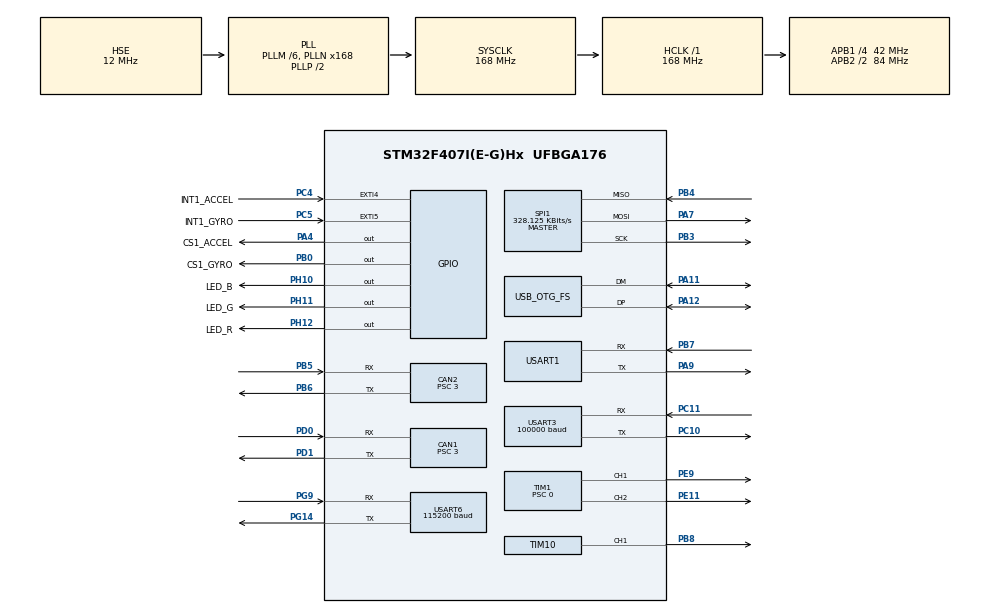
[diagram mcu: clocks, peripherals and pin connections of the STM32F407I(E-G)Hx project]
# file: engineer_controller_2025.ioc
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CAN1.ABOM=ENABLE
CAN1.AWUM=ENABLE
CAN1.BS1=CAN_BS1_7TQ
CAN1.BS2=CAN_BS2_6TQ
CAN1.CalculateBaudRate=1000000
CAN1.CalculateTimeBit=1000
CAN1.CalculateTimeQuantum=71.42857142857143
CAN1.Mode=CAN_MODE_NORMAL
CAN1.NART=ENABLE
CAN1.Prescaler=3
CAN1.TXFP=ENABLE
CAN2.ABOM=ENABLE
CAN2.AWUM=ENABLE
CAN2.BS1=CAN_BS1_7TQ
CAN2.BS2=CAN_BS2_6TQ
CAN2.CalculateBaudRate=1000000
CAN2.CalculateTimeBit=1000
CAN2.CalculateTimeQuantum=71.42857142857143
CAN2.NART=ENABLE
CAN2.Prescaler=3
CAN2.RFLM=DISABLE
CAN2.TTCM=DISABLE
CAN2.TXFP=ENABLE
Dma.Request0=USART3_RX
Dma.Request1=SPI1_RX
Dma.Request2=SPI1_TX
Dma.Request3=TIM1_CH1
Dma.Request4=TIM1_CH2
Dma.Request5=USART1_RX
Dma.Request6=USART1_TX
Dma.SPI1_RX.1.Direction=DMA_PERIPH_TO_MEMORY
Dma.SPI1_RX.1.FIFOMode=DMA_FIFOMODE_DISABLE
Dma.SPI1_RX.1.Instance=DMA2_Stream0
Dma.SPI1_RX.1.MemDataAlignment=DMA_MDATAALIGN_BYTE
Dma.SPI1_RX.1.MemInc=DMA_MINC_ENABLE
Dma.SPI1_RX.1.Mode=DMA_NORMAL
Dma.SPI1_RX.1.PeriphDataAlignment=DMA_PDATAALIGN_BYTE
Dma.SPI1_RX.1.PeriphInc=DMA_PINC_DISABLE
Dma.SPI1_RX.1.Priority=DMA_PRIORITY_VERY_HIGH
Dma.SPI1_TX.2.Direction=DMA_MEMORY_TO_PERIPH
Dma.SPI1_TX.2.FIFOMode=DMA_FIFOMODE_DISABLE
Dma.SPI1_TX.2.Instance=DMA2_Stream3
Dma.SPI1_TX.2.MemDataAlignment=DMA_MDATAALIGN_BYTE
Dma.SPI1_TX.2.MemInc=DMA_MINC_ENABLE
Dma.SPI1_TX.2.Mode=DMA_NORMAL
Dma.SPI1_TX.2.PeriphDataAlignment=DMA_PDATAALIGN_BYTE
Dma.SPI1_TX.2.PeriphInc=DMA_PINC_DISABLE
Dma.SPI1_TX.2.Priority=DMA_PRIORITY_VERY_HIGH
Dma.TIM1_CH1.3.Direction=DMA_MEMORY_TO_PERIPH
Dma.TIM1_CH1.3.FIFOMode=DMA_FIFOMODE_DISABLE
Dma.TIM1_CH1.3.Instance=DMA2_Stream1
Dma.TIM1_CH1.3.MemDataAlignment=DMA_MDATAALIGN_HALFWORD
Dma.TIM1_CH1.3.MemInc=DMA_MINC_ENABLE
Dma.TIM1_CH1.3.Mode=DMA_CIRCULAR
Dma.TIM1_CH1.3.PeriphDataAlignment=DMA_PDATAALIGN_HALFWORD
Dma.TIM1_CH1.3.PeriphInc=DMA_PINC_DISABLE
Dma.TIM1_CH1.3.Priority=DMA_PRIORITY_HIGH
Dma.TIM1_CH2.4.Direction=DMA_MEMORY_TO_PERIPH
Dma.TIM1_CH2.4.FIFOMode=DMA_FIFOMODE_DISABLE
Dma.TIM1_CH2.4.Instance=DMA2_Stream2
Dma.TIM1_CH2.4.MemDataAlignment=DMA_MDATAALIGN_HALFWORD
Dma.TIM1_CH2.4.MemInc=DMA_MINC_ENABLE
Dma.TIM1_CH2.4.Mode=DMA_NORMAL
Dma.TIM1_CH2.4.PeriphDataAlignment=DMA_PDATAALIGN_HALFWORD
Dma.TIM1_CH2.4.PeriphInc=DMA_PINC_DISABLE
Dma.TIM1_CH2.4.Priority=DMA_PRIORITY_HIGH
Dma.USART1_RX.5.Direction=DMA_PERIPH_TO_MEMORY
Dma.USART1_RX.5.FIFOMode=DMA_FIFOMODE_DISABLE
Dma.USART1_RX.5.Instance=DMA2_Stream5
Dma.USART1_RX.5.MemDataAlignment=DMA_MDATAALIGN_BYTE
Dma.USART1_RX.5.MemInc=DMA_MINC_ENABLE
Dma.USART1_RX.5.Mode=DMA_NORMAL
Dma.USART1_RX.5.PeriphDataAlignment=DMA_PDATAALIGN_BYTE
Dma.USART1_RX.5.PeriphInc=DMA_PINC_DISABLE
Dma.USART1_RX.5.Priority=DMA_PRIORITY_LOW
Dma.USART1_TX.6.Direction=DMA_MEMORY_TO_PERIPH
Dma.USART1_TX.6.FIFOMode=DMA_FIFOMODE_DISABLE
Dma.USART1_TX.6.Instance=DMA2_Stream7
Dma.USART1_TX.6.MemDataAlignment=DMA_MDATAALIGN_BYTE
Dma.USART1_TX.6.MemInc=DMA_MINC_ENABLE
Dma.USART1_TX.6.Mode=DMA_NORMAL
Dma.USART1_TX.6.PeriphDataAlignment=DMA_PDATAALIGN_BYTE
Dma.USART1_TX.6.PeriphInc=DMA_PINC_DISABLE
Dma.USART1_TX.6.Priority=DMA_PRIORITY_LOW
Dma.USART3_RX.0.Direction=DMA_PERIPH_TO_MEMORY
Dma.USART3_RX.0.FIFOMode=DMA_FIFOMODE_DISABLE
Dma.USART3_RX.0.Instance=DMA1_Stream1
Dma.USART3_RX.0.MemDataAlignment=DMA_MDATAALIGN_BYTE
Dma.USART3_RX.0.MemInc=DMA_MINC_ENABLE
Dma.USART3_RX.0.Mode=DMA_NORMAL
Dma.USART3_RX.0.PeriphDataAlignment=DMA_PDATAALIGN_BYTE
Dma.USART3_RX.0.PeriphInc=DMA_PINC_DISABLE
Dma.USART3_RX.0.Priority=DMA_PRIORITY_HIGH
FREERTOS.BinarySemaphores01=judgementInitBinarySem,Dynamic,NULL,Depleted;ArmMotor1UpdateBinarySem,Dynamic,NULL,Depleted;ArmMotor2UpdateBinarySem,Dynamic,NULL,Depleted;ArmMotor3UpdateBinarySem,Dynamic,NULL,Depleted;ArmMotor4UpdateBinarySem,Dynamic,NULL,Depleted;ArmMotor5UpdateBinarySem,Dynamic,NULL,Depleted;ArmMotor6UpdateBinarySem,Dynamic,NULL,Depleted
FREERTOS.CountingSemaphores01=CAN1CountingSem,3,Dynamic,NULL,3;CAN2CountingSem,3,Dynamic,NULL,3
FREERTOS.Events01=refereeEvent,Dynamic,NULL
FREERTOS.Queues01=CAN1SendQueue,16,can_device_transmit_member,0,Dynamic,NULL,NULL;CAN2SendQueue,16,can_device_transmit_member,0,Dynamic,NULL,NULL
FREERTOS.Tasks01=defaultTask,24,256,StartDefaultTask,Default,NULL,Dynamic,NULL,NULL;CAN1_Send_Task,40,256,CAN1Send_Task,As weak,NULL,Dynamic,NULL,NULL;CAN2_Send_Task,40,256,CAN2Send_Task,As weak,NULL,Dynamic,NULL,NULL;judgeCtrltask,24,256,judgeCtrl_task,As weak,NULL,Dynamic,NULL,NULL;armtask,24,256,arm_task,As weak,NULL,Dynamic,NULL,NULL;refereeupdatetask,24,256,refereeupdate_task,As weak,NULL,Dynamic,NULL,NULL;lostchecktask,24,512,lost_check_task,As weak,NULL,Dynamic,NULL,NULL
FREERTOS.configMAX_TASK_NAME_LEN=32
FREERTOS.configMINIMAL_STACK_SIZE=128
FREERTOS.configTOTAL_HEAP_SIZE=80000
FREERTOS.configUSE_NEWLIB_REENTRANT=1
IWDG.Prescaler=IWDG_PRESCALER_4
Mcu.Family=STM32F4
Mcu.Name=STM32F407I(E-G)Hx
Mcu.Package=UFBGA176
NVIC.CAN1_RX0_IRQn=true\:5\:0\:false\:false\:true\:true\:true\:true\:true
NVIC.CAN1_TX_IRQn=true\:5\:0\:false\:false\:true\:true\:true\:true\:true
NVIC.CAN2_RX1_IRQn=true\:5\:0\:false\:false\:true\:true\:true\:true\:true
NVIC.CAN2_TX_IRQn=true\:5\:0\:false\:false\:true\:true\:true\:true\:true
NVIC.DMA1_Stream1_IRQn=true\:5\:0\:false\:false\:true\:true\:false\:true\:true
NVIC.DMA2_Stream0_IRQn=true\:5\:0\:false\:false\:true\:false\:false\:true\:true
NVIC.DMA2_Stream1_IRQn=true\:5\:0\:false\:false\:true\:false\:false\:true\:true
NVIC.DMA2_Stream2_IRQn=true\:5\:0\:false\:false\:true\:true\:false\:true\:true
NVIC.DMA2_Stream3_IRQn=true\:5\:0\:false\:false\:true\:true\:false\:true\:true
NVIC.DMA2_Stream5_IRQn=true\:5\:0\:false\:false\:true\:true\:false\:true\:true
NVIC.DMA2_Stream7_IRQn=true\:5\:0\:false\:false\:true\:true\:false\:true\:true
NVIC.OTG_FS_IRQn=true\:5\:0\:false\:false\:true\:true\:false\:true\:true
NVIC.PriorityGroup=NVIC_PRIORITYGROUP_4
NVIC.TIM7_IRQn=true\:0\:0\:true\:false\:true\:false\:false\:true\:true
NVIC.TimeBase=TIM7_IRQn
NVIC.TimeBaseIP=TIM7
NVIC.USART1_IRQn=true\:5\:0\:false\:false\:true\:true\:true\:true\:true
NVIC.USART3_IRQn=true\:5\:0\:false\:false\:true\:true\:true\:true\:true
NVIC.USART6_IRQn=true\:5\:0\:false\:false\:true\:true\:true\:true\:true
PA11.Mode=Device_Only
PA11.Signal=USB_OTG_FS_DM
PA12.Mode=Device_Only
PA12.Signal=USB_OTG_FS_DP
PA13.Mode=Serial_Wire
PA13.Signal=SYS_JTMS-SWDIO
PA14.Mode=Serial_Wire
PA14.Signal=SYS_JTCK-SWCLK
PA4.GPIO_Label=CS1_ACCEL
PA4.GPIO_PuPd=GPIO_PULLUP
PA4.GPIO_Speed=GPIO_SPEED_FREQ_HIGH
PA4.PinState=GPIO_PIN_SET
PA4.Signal=GPIO_Output
PA7.Mode=Full_Duplex_Master
PA7.Signal=SPI1_MOSI
PA9.Mode=Asynchronous
PA9.Signal=USART1_TX
PB0.GPIO_Label=CS1_GYRO
PB0.GPIO_PuPd=GPIO_PULLUP
PB0.GPIO_Speed=GPIO_SPEED_FREQ_HIGH
PB0.PinState=GPIO_PIN_SET
PB0.Signal=GPIO_Output
PB3.Mode=Full_Duplex_Master
PB3.Signal=SPI1_SCK
PB4.Mode=Full_Duplex_Master
PB4.Signal=SPI1_MISO
PB5.Mode=CAN_Activate
PB5.Signal=CAN2_RX
PB6.Mode=CAN_Activate
PB6.Signal=CAN2_TX
PB7.Mode=Asynchronous
PB7.Signal=USART1_RX
PB8.Signal=S_TIM10_CH1
PC10.Mode=Asynchronous
PC10.Signal=USART3_TX
PC11.Mode=Asynchronous
PC11.Signal=USART3_RX
PC4.GPIO_Label=INT1_ACCEL
PC4.GPIO_PuPd=GPIO_PULLUP
PC4.Signal=GPXTI4
PC5.GPIO_Label=INT1_GYRO
PC5.GPIO_PuPd=GPIO_PULLUP
PC5.Signal=GPXTI5
PD0.Mode=CAN_Activate
PD0.Signal=CAN1_RX
PD1.Mode=CAN_Activate
PD1.Signal=CAN1_TX
PE11.Signal=S_TIM1_CH2
PE9.Signal=S_TIM1_CH1
PG14.Mode=Asynchronous
PG14.Signal=USART6_TX
PG9.Mode=Asynchronous
PG9.Signal=USART6_RX
PH0-OSC_IN.Mode=HSE-External-Oscillator
PH0-OSC_IN.Signal=RCC_OSC_IN
PH1-OSC_OUT.Mode=HSE-External-Oscillator
PH1-OSC_OUT.Signal=RCC_OSC_OUT
PH10.GPIO_Label=LED_B
PH10.GPIO_PuPd=GPIO_PULLDOWN
PH10.Signal=GPIO_Output
PH11.GPIO_Label=LED_G
PH11.GPIO_PuPd=GPIO_PULLDOWN
PH11.Signal=GPIO_Output
PH12.GPIO_Label=LED_R
PH12.GPIO_PuPd=GPIO_PULLDOWN
PH12.Signal=GPIO_Output
ProjectManager.HeapSize=0x200
ProjectManager.StackSize=0x400
ProjectManager.TargetToolchain=STM32CubeIDE
RCC.48MHZClocksFreq_Value=48000000
RCC.AHBFreq_Value=168000000
RCC.APB1CLKDivider=RCC_HCLK_DIV4
RCC.APB1Freq_Value=42000000
RCC.APB1TimFreq_Value=84000000
RCC.APB2CLKDivider=RCC_HCLK_DIV2
RCC.APB2Freq_Value=84000000
RCC.APB2TimFreq_Value=168000000
RCC.CortexFreq_Value=168000000
RCC.HCLKFreq_Value=168000000
RCC.HSE_VALUE=12000000
RCC.HSI_VALUE=16000000
RCC.LSE_VALUE=32768
RCC.PLLM=6
RCC.PLLN=168
RCC.PLLQ=7
RCC.SYSCLKFreq_VALUE=168000000
RCC.SYSCLKSource=RCC_SYSCLKSOURCE_PLLCLK
RCC.VCOOutputFreq_Value=336000000
SH.S_TIM10_CH1.0=TIM10_CH1,PWM Generation1 CH1
SH.S_TIM1_CH1.0=TIM1_CH1,PWM Generation1 CH1
SH.S_TIM1_CH2.0=TIM1_CH2,PWM Generation2 CH2
SPI1.BaudRatePrescaler=SPI_BAUDRATEPRESCALER_256
SPI1.CLKPhase=SPI_PHASE_2EDGE
SPI1.CLKPolarity=SPI_POLARITY_HIGH
SPI1.CalculateBaudRate=328.125 KBits/s
SPI1.Direction=SPI_DIRECTION_2LINES
SPI1.Mode=SPI_MODE_MASTER
SPI1.VirtualType=VM_MASTER
STMicroelectronics.X-CUBE-ALGOBUILD.1.3.0.LibraryCcDSPOoLibraryJjDSPOoLibrary=true
TIM1.AutoReloadPreload=TIM_AUTORELOAD_PRELOAD_DISABLE
TIM1.Channel-PWM\ Generation1\ CH1=TIM_CHANNEL_1
TIM1.Channel-PWM\ Generation2\ CH2=TIM_CHANNEL_2
TIM1.Period=210-1
TIM1.Prescaler=0
TIM10.Channel=TIM_CHANNEL_1
TIM10.Period=5000-1
USART1.VirtualMode=VM_ASYNC
USART3.BaudRate=100000
USART3.Parity=PARITY_EVEN
USART3.VirtualMode=VM_ASYNC
USART3.WordLength=WORDLENGTH_9B
USART6.BaudRate=115200
USART6.VirtualMode=VM_ASYNC
USB_DEVICE.CLASS_NAME_FS=CDC
USB_DEVICE.VirtualMode-CDC_FS=Cdc
USB_DEVICE.VirtualModeFS=Cdc_FS
USB_OTG_FS.VirtualMode=Device_Only
VP_FREERTOS_VS_CMSIS_V2.Mode=CMSIS_V2
VP_IWDG_VS_IWDG.Mode=IWDG_Activate
VP_STMicroelectronics.X-CUBE-ALGOBUILD_VS_DSPOoLibraryJjLibrary_1.3.0_1.3.0.Mode=DSPOoLibraryJjLibrary
VP_SYS_VS_tim7.Mode=TIM7
VP_TIM10_VS_ClockSourceINT.Mode=Enable_Timer
VP_TIM1_VS_ClockSourceINT.Mode=Internal
VP_USB_DEVICE_VS_USB_DEVICE_CDC_FS.Mode=CDC_FS
board=custom

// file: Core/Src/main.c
/* USER CODE BEGIN Header */
/**
  ******************************************************************************
  * @file           : main.c
  * @brief          : Main program body
  ******************************************************************************
  * @attention
  *
  * Copyright (c) 2025 STMicroelectronics.
  * All rights reserved.
  *
  * This software is licensed under terms that can be found in the LICENSE file
  * in the root directory of this software component.
  * If no LICENSE file comes with this software, it is provided AS-IS.
  *
  ******************************************************************************
  */
/* USER CODE END Header */
#include "main.h"
#include "cmsis_os.h"
#include "can.h"
#include "dma.h"
#include "iwdg.h"
#include "spi.h"
#include "tim.h"
#include "usart.h"
#include "usb_device.h"
#include "gpio.h"

/* USER CODE BEGIN Includes */
#include "compatible.h"
#include "bsp_dwt.h"
/* USER CODE END Includes */

void SystemClock_Config(void);
void MX_FREERTOS_Init(void);

int main(void)
{

  /* USER CODE BEGIN 1 */
    __HAL_RCC_SYSCLK_CONFIG(RCC_SYSCLKSOURCE_HSI);
  /* USER CODE END 1 */

  /* MCU Configuration--------------------------------------------------------*/

  /* Reset of all peripherals, Initializes the Flash interface and the Systick. */
  HAL_Init();

  /* Configure the system clock */
  SystemClock_Config();

  /* Initialize all configured peripherals */
  MX_GPIO_Init();
  MX_DMA_Init();
  MX_CAN1_Init();
  MX_CAN2_Init();
  MX_TIM1_Init();
  MX_USART3_UART_Init();
  MX_SPI1_Init();
  MX_TIM10_Init();
  MX_USART6_UART_Init();
  MX_IWDG_Init();
  MX_USART1_UART_Init();
  /* USER CODE BEGIN 2 */
    DWT_Init(168);
    bsp_can_init();
  /* USER CODE END 2 */

  /* Init scheduler */
  osKernelInitialize();  /* Call init function for freertos objects (in cmsis_os2.c) */
  MX_FREERTOS_Init();

  /* Start scheduler */
  osKernelStart();

  /* We should never get here as control is now taken by the scheduler */

  /* Infinite loop */
  while (1)
  {

  }
}

void SystemClock_Config(void)
{
  RCC_OscInitTypeDef RCC_OscInitStruct = {0};
  RCC_ClkInitTypeDef RCC_ClkInitStruct = {0};

  /** Configure the main internal regulator output voltage
  */
  __HAL_RCC_PWR_CLK_ENABLE();
  __HAL_PWR_VOLTAGESCALING_CONFIG(PWR_REGULATOR_VOLTAGE_SCALE1);

  /** Initializes the RCC Oscillators according to the specified parameters
  * in the RCC_OscInitTypeDef structure.
  */
  RCC_OscInitStruct.OscillatorType = RCC_OSCILLATORTYPE_LSI|RCC_OSCILLATORTYPE_HSE;
  RCC_OscInitStruct.HSEState = RCC_HSE_ON;
  RCC_OscInitStruct.LSIState = RCC_LSI_ON;
  RCC_OscInitStruct.PLL.PLLState = RCC_PLL_ON;
  RCC_OscInitStruct.PLL.PLLSource = RCC_PLLSOURCE_HSE;
  RCC_OscInitStruct.PLL.PLLM = 6;
  RCC_OscInitStruct.PLL.PLLN = 168;
  RCC_OscInitStruct.PLL.PLLP = RCC_PLLP_DIV2;
  RCC_OscInitStruct.PLL.PLLQ = 7;
  if (HAL_RCC_OscConfig(&RCC_OscInitStruct) != HAL_OK)
  {
    Error_Handler();
  }

  /** Initializes the CPU, AHB and APB buses clocks
  */
  RCC_ClkInitStruct.ClockType = RCC_CLOCKTYPE_HCLK|RCC_CLOCKTYPE_SYSCLK
                              |RCC_CLOCKTYPE_PCLK1|RCC_CLOCKTYPE_PCLK2;
  RCC_ClkInitStruct.SYSCLKSource = RCC_SYSCLKSOURCE_PLLCLK;
  RCC_ClkInitStruct.AHBCLKDivider = RCC_SYSCLK_DIV1;
  RCC_ClkInitStruct.APB1CLKDivider = RCC_HCLK_DIV4;
  RCC_ClkInitStruct.APB2CLKDivider = RCC_HCLK_DIV2;

  if (HAL_RCC_ClockConfig(&RCC_ClkInitStruct, FLASH_LATENCY_5) != HAL_OK)
  {
    Error_Handler();
  }
}

void HAL_TIM_PeriodElapsedCallback(TIM_HandleTypeDef *htim)
{
  if (htim->Instance == TIM7)
  {
    HAL_IncTick();
  }
}

void Error_Handler(void)
{
  __disable_irq();
  while (1)
  {
  }
}

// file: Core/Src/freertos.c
/* USER CODE BEGIN Header */
/**
  ******************************************************************************
  * File Name          : freertos.c
  * Description        : Code for freertos applications
  ******************************************************************************
  * @attention
  *
  * Copyright (c) 2025 STMicroelectronics.
  * All rights reserved.
  *
  * This software is licensed under terms that can be found in the LICENSE file
  * in the root directory of this software component.
  * If no LICENSE file comes with this software, it is provided AS-IS.
  *
  ******************************************************************************
  */
/* USER CODE END Header */

#include "FreeRTOS.h"
#include "task.h"
#include "main.h"
#include "cmsis_os.h"

/* USER CODE BEGIN Includes */
#include "compatible.h"
#include "iwdg.h"
/* USER CODE END Includes */

/* Definitions for defaultTask */
osThreadId_t defaultTaskHandle;
const osThreadAttr_t defaultTask_attributes = {
  .name = "defaultTask",
  .stack_size = 256 * 4,
  .priority = (osPriority_t) osPriorityNormal,
};
/* Definitions for CAN1_Send_Task */
osThreadId_t CAN1_Send_TaskHandle;
const osThreadAttr_t CAN1_Send_Task_attributes = {
  .name = "CAN1_Send_Task",
  .stack_size = 256 * 4,
  .priority = (osPriority_t) osPriorityHigh,
};
/* Definitions for CAN2_Send_Task */
osThreadId_t CAN2_Send_TaskHandle;
const osThreadAttr_t CAN2_Send_Task_attributes = {
  .name = "CAN2_Send_Task",
  .stack_size = 256 * 4,
  .priority = (osPriority_t) osPriorityHigh,
};
/* Definitions for judgeCtrltask */
osThreadId_t judgeCtrltaskHandle;
const osThreadAttr_t judgeCtrltask_attributes = {
  .name = "judgeCtrltask",
  .stack_size = 256 * 4,
  .priority = (osPriority_t) osPriorityNormal,
};
/* Definitions for armtask */
osThreadId_t armtaskHandle;
const osThreadAttr_t armtask_attributes = {
  .name = "armtask",
  .stack_size = 256 * 4,
  .priority = (osPriority_t) osPriorityNormal,
};
/* Definitions for refereeupdatetask */
osThreadId_t refereeupdatetaskHandle;
const osThreadAttr_t refereeupdatetask_attributes = {
  .name = "refereeupdatetask",
  .stack_size = 256 * 4,
  .priority = (osPriority_t) osPriorityNormal,
};
/* Definitions for lostchecktask */
osThreadId_t lostchecktaskHandle;
const osThreadAttr_t lostchecktask_attributes = {
  .name = "lostchecktask",
  .stack_size = 512 * 4,
  .priority = (osPriority_t) osPriorityNormal,
};
/* Definitions for CAN1SendQueue */
osMessageQueueId_t CAN1SendQueueHandle;
const osMessageQueueAttr_t CAN1SendQueue_attributes = {
  .name = "CAN1SendQueue"
};
/* Definitions for CAN2SendQueue */
osMessageQueueId_t CAN2SendQueueHandle;
const osMessageQueueAttr_t CAN2SendQueue_attributes = {
  .name = "CAN2SendQueue"
};
/* Definitions for judgementInitBinarySem */
osSemaphoreId_t judgementInitBinarySemHandle;
const osSemaphoreAttr_t judgementInitBinarySem_attributes = {
  .name = "judgementInitBinarySem"
};
/* Definitions for ArmMotor1UpdateBinarySem */
osSemaphoreId_t ArmMotor1UpdateBinarySemHandle;
const osSemaphoreAttr_t ArmMotor1UpdateBinarySem_attributes = {
  .name = "ArmMotor1UpdateBinarySem"
};
/* Definitions for ArmMotor2UpdateBinarySem */
osSemaphoreId_t ArmMotor2UpdateBinarySemHandle;
const osSemaphoreAttr_t ArmMotor2UpdateBinarySem_attributes = {
  .name = "ArmMotor2UpdateBinarySem"
};
/* Definitions for ArmMotor3UpdateBinarySem */
osSemaphoreId_t ArmMotor3UpdateBinarySemHandle;
const osSemaphoreAttr_t ArmMotor3UpdateBinarySem_attributes = {
  .name = "ArmMotor3UpdateBinarySem"
};
/* Definitions for ArmMotor4UpdateBinarySem */
osSemaphoreId_t ArmMotor4UpdateBinarySemHandle;
const osSemaphoreAttr_t ArmMotor4UpdateBinarySem_attributes = {
  .name = "ArmMotor4UpdateBinarySem"
};
/* Definitions for ArmMotor5UpdateBinarySem */
osSemaphoreId_t ArmMotor5UpdateBinarySemHandle;
const osSemaphoreAttr_t ArmMotor5UpdateBinarySem_attributes = {
  .name = "ArmMotor5UpdateBinarySem"
};
/* Definitions for ArmMotor6UpdateBinarySem */
osSemaphoreId_t ArmMotor6UpdateBinarySemHandle;
const osSemaphoreAttr_t ArmMotor6UpdateBinarySem_attributes = {
  .name = "ArmMotor6UpdateBinarySem"
};
/* Definitions for CAN1CountingSem */
osSemaphoreId_t CAN1CountingSemHandle;
const osSemaphoreAttr_t CAN1CountingSem_attributes = {
  .name = "CAN1CountingSem"
};
/* Definitions for CAN2CountingSem */
osSemaphoreId_t CAN2CountingSemHandle;
const osSemaphoreAttr_t CAN2CountingSem_attributes = {
  .name = "CAN2CountingSem"
};
/* Definitions for refereeEvent */
osEventFlagsId_t refereeEventHandle;
const osEventFlagsAttr_t refereeEvent_attributes = {
  .name = "refereeEvent"
};

void StartDefaultTask(void *argument);
void CAN1Send_Task(void *argument);
void CAN2Send_Task(void *argument);
void judgeCtrl_task(void *argument);
void arm_task(void *argument);
void refereeupdate_task(void *argument);
void lost_check_task(void *argument);

extern void MX_USB_DEVICE_Init(void);
void MX_FREERTOS_Init(void); /* (MISRA C 2004 rule 8.1) */

void MX_FREERTOS_Init(void) {

  /* Create the semaphores(s) */
  /* creation of judgementInitBinarySem */
  judgementInitBinarySemHandle = osSemaphoreNew(1, 0, &judgementInitBinarySem_attributes);

  /* creation of ArmMotor1UpdateBinarySem */
  ArmMotor1UpdateBinarySemHandle = osSemaphoreNew(1, 0, &ArmMotor1UpdateBinarySem_attributes);

  /* creation of ArmMotor2UpdateBinarySem */
  ArmMotor2UpdateBinarySemHandle = osSemaphoreNew(1, 0, &ArmMotor2UpdateBinarySem_attributes);

  /* creation of ArmMotor3UpdateBinarySem */
  ArmMotor3UpdateBinarySemHandle = osSemaphoreNew(1, 0, &ArmMotor3UpdateBinarySem_attributes);

  /* creation of ArmMotor4UpdateBinarySem */
  ArmMotor4UpdateBinarySemHandle = osSemaphoreNew(1, 0, &ArmMotor4UpdateBinarySem_attributes);

  /* creation of ArmMotor5UpdateBinarySem */
  ArmMotor5UpdateBinarySemHandle = osSemaphoreNew(1, 0, &ArmMotor5UpdateBinarySem_attributes);

  /* creation of ArmMotor6UpdateBinarySem */
  ArmMotor6UpdateBinarySemHandle = osSemaphoreNew(1, 0, &ArmMotor6UpdateBinarySem_attributes);

  /* creation of CAN1CountingSem */
  CAN1CountingSemHandle = osSemaphoreNew(3, 3, &CAN1CountingSem_attributes);

  /* creation of CAN2CountingSem */
  CAN2CountingSemHandle = osSemaphoreNew(3, 3, &CAN2CountingSem_attributes);

  /* Create the queue(s) */
  /* creation of CAN1SendQueue */
  CAN1SendQueueHandle = osMessageQueueNew (16, sizeof(can_device_transmit_member), &CAN1SendQueue_attributes);

  /* creation of CAN2SendQueue */
  CAN2SendQueueHandle = osMessageQueueNew (16, sizeof(can_device_transmit_member), &CAN2SendQueue_attributes);

  /* Create the thread(s) */
  /* creation of defaultTask */
  defaultTaskHandle = osThreadNew(StartDefaultTask, NULL, &defaultTask_attributes);

  /* creation of CAN1_Send_Task */
  CAN1_Send_TaskHandle = osThreadNew(CAN1Send_Task, NULL, &CAN1_Send_Task_attributes);

  /* creation of CAN2_Send_Task */
  CAN2_Send_TaskHandle = osThreadNew(CAN2Send_Task, NULL, &CAN2_Send_Task_attributes);

  /* creation of judgeCtrltask */
  judgeCtrltaskHandle = osThreadNew(judgeCtrl_task, NULL, &judgeCtrltask_attributes);

  /* creation of armtask */
  armtaskHandle = osThreadNew(arm_task, NULL, &armtask_attributes);

  /* creation of refereeupdatetask */
  refereeupdatetaskHandle = osThreadNew(refereeupdate_task, NULL, &refereeupdatetask_attributes);

  /* creation of lostchecktask */
  lostchecktaskHandle = osThreadNew(lost_check_task, NULL, &lostchecktask_attributes);

  /* Create the event(s) */
  /* creation of refereeEvent */
  refereeEventHandle = osEventFlagsNew(&refereeEvent_attributes);

}

void StartDefaultTask(void *argument)
{
  /* init code for USB_DEVICE */
  MX_USB_DEVICE_Init();
  /* USER CODE BEGIN StartDefaultTask */
  /* Infinite loop */
  for(;;)
  {
      HAL_IWDG_Refresh(&hiwdg);//(625-1+1)*64/32000s
      HAL_GPIO_TogglePin(LED_G_GPIO_Port, LED_R_Pin);
      osDelay(200);
//      HAL_GPIO_TogglePin(LED_G_GPIO_Port, LED_G_Pin);
//      osDelay(200);
      HAL_GPIO_TogglePin(LED_G_GPIO_Port, LED_B_Pin);
      osDelay(200);
  }
  /* USER CODE END StartDefaultTask */
}

__weak void CAN1Send_Task(void *argument)
{
  for(;;)
  {
    osDelay(1);
  }
}

__weak void CAN2Send_Task(void *argument)
{
  for(;;)
  {
    osDelay(1);
  }
}

__weak void judgeCtrl_task(void *argument)
{
  for(;;)
  {
    osDelay(1);
  }
}

__weak void arm_task(void *argument)
{
  for(;;)
  {
    osDelay(1);
  }
}

__weak void refereeupdate_task(void *argument)
{
  for(;;)
  {
    osDelay(1);
  }
}

__weak void lost_check_task(void *argument)
{
  for(;;)
  {
    osDelay(1);
  }
}
